VERSION "GB/T 27930-2015 canonical charger/BMS message set (canfd.net reference; extracted 2026-09-05)"

NS_ :

BS_:

BU_: Charger BMS

BO_ 2552689750 CHM: 3 Charger
 SG_ ChargerVersion : 8|16@1+ (1,0) [0|65535] ""  BMS
 SG_ ChargerRevision : 0|8@1+ (1,0) [0|255] ""  BMS

BO_ 2552714996 BHM: 2 Charger
 SG_ MaxChargingVoltage : 0|16@1+ (0.1,0) [0|6553.5] "V" Charger

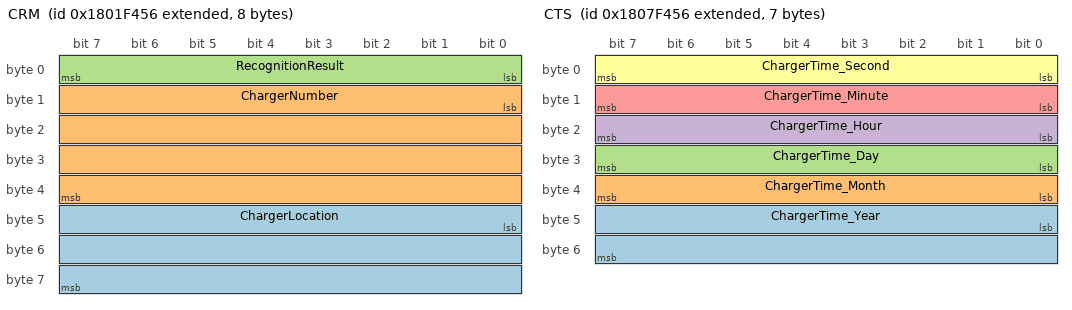
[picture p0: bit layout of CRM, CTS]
BO_ 2550264918 CRM: 8 Charger
 SG_ ChargerLocation : 40|24@1+ (1,0) [0|16777215] ""  BMS
 SG_ ChargerNumber : 8|32@1+ (1,0) [0|4294967295] ""  BMS
 SG_ RecognitionResult : 0|8@1+ (1,0) [0|170] ""  BMS

BO_ 2617442292 BRM: 49 Charger
 SG_ VIN_Copy_17 : 320|8@1+ (1,0) [0|255] "" Charger
 SG_ VIN_Copy_16 : 312|8@1+ (1,0) [0|255] "" Charger
 SG_ VIN_Copy_15 : 304|8@1+ (1,0) [0|255] "" Charger
 SG_ VIN_Copy_14 : 296|8@1+ (1,0) [0|255] "" Charger
 SG_ VIN_Copy_13 : 288|8@1+ (1,0) [0|255] "" Charger
 SG_ VIN_Copy_12 : 280|8@1+ (1,0) [0|255] "" Charger
 SG_ VIN_Copy_11 : 272|8@1+ (1,0) [0|255] "" Charger
 SG_ VIN_Copy_10 : 264|8@1+ (1,0) [0|255] "" Charger
 SG_ VIN_Copy_9 : 256|8@1+ (1,0) [0|255] "" Charger
 SG_ VIN_Copy_8 : 248|8@1+ (1,0) [0|255] "" Charger
 SG_ VIN_Copy_7 : 240|8@1+ (1,0) [0|255] "" Charger
 SG_ VIN_Copy_6 : 232|8@1+ (1,0) [0|255] "" Charger
 SG_ VIN_Copy_5 : 224|8@1+ (1,0) [0|255] "" Charger
 SG_ VIN_Copy_4 : 216|8@1+ (1,0) [0|255] "" Charger
 SG_ VIN_Copy_3 : 208|8@1+ (1,0) [0|255] "" Charger
 SG_ VIN_Copy_2 : 200|8@1+ (1,0) [0|255] "" Charger
 SG_ VIN_Copy_1 : 192|8@1+ (1,0) [0|255] "" Charger
 SG_ BmsSoftwareVersion_Reserved : 368|24@1+ (1,0) [0|16777215] "" Charger
 SG_ BmsSoftwareVersion_CompileYear : 352|16@1+ (1,0) [0|65534] "" Charger
 SG_ BmsSoftwareVersion_CompileMonth : 344|8@1+ (1,0) [1|12] "" Charger
 SG_ BmsSoftwareVersion_CompileDay : 336|8@1+ (1,0) [1|31] "" Charger
 SG_ BmsSoftwareVersion_Serial : 328|8@1+ (1,0) [1|254] "" Charger
 SG_ BRM_Reserved1 : 184|8@1+ (1,0) [0|255] "" Charger
 SG_ Property : 176|8@1+ (1,0) [0|1] "" Charger
 SG_ ChargingFrequency : 152|24@1+ (1,0) [0|16777215] "" Charger
 SG_ ProductionDay : 144|8@1+ (1,0) [0|31] "Days" Charger
 SG_ ProductionMonth : 136|8@1+ (1,0) [1|12] "" Charger
 SG_ ProductionYear : 128|8@1+ (1,1985) [1985|2235] "Years" Charger
 SG_ BatteryPackNumber : 96|32@1+ (1,0) [0|4294967295] "" Charger
 SG_ ManufacturerName : 64|32@1+ (1,0) [0|4294967295] "" Charger
 SG_ BatterySystemVoltage : 48|16@1+ (0.1,0) [0|6553.5] "V" Charger
 SG_ BatterySystemCapacity : 32|16@1+ (0.1,0) [0|6553.5] "Ah" Charger
 SG_ BmsVersion : 8|16@1+ (1,0) [0|65535] "" Charger
 SG_ BmsRevision : 0|8@1+ (1,0) [0|255] "" Charger
 SG_ BatteryType : 24|8@1+ (1,0) [0|255] "" Charger

BO_ 2617704436 BCP: 13 Charger
 SG_ CurrentVehicleBatteryVoltage : 88|16@1+ (0.1,0) [0|6553.5] "V" Charger
 SG_ StatusVehiclePowerStorageBattery : 72|16@1+ (0.1,0) [0|100] "%" Charger
 SG_ MaxPermTemperature : 64|8@1+ (1,-50) [-50|200] "" Charger
 SG_ TotalMaxPermChargingVoltage : 48|16@1+ (0.1,0) [0|6553.5] "V" Charger
 SG_ TotalNominalEnergy : 32|16@1+ (0.1,0) [0|1000] "kWh" Charger
 SG_ MaxPermChargingCurrent : 16|16@1+ (0.1,-400) [-400|6153.5] "A" Charger
 SG_ MaxSingleBattChargingVoltage : 0|16@1+ (0.01,0) [0|24] "V" Charger

BO_ 2550658134 CTS: 7 Charger
 SG_ ChargerTime_Year : 40|16@1+ (1,0) [0|39321] ""  BMS
 SG_ ChargerTime_Month : 32|8@1+ (1,0) [0|18] ""  BMS
 SG_ ChargerTime_Day : 24|8@1+ (1,0) [0|49] ""  BMS
 SG_ ChargerTime_Hour : 16|8@1+ (1,0) [0|36] ""  BMS
 SG_ ChargerTime_Minute : 8|8@1+ (1,0) [0|96] ""  BMS
 SG_ ChargerTime_Second : 0|8@1+ (1,0) [0|96] ""  BMS

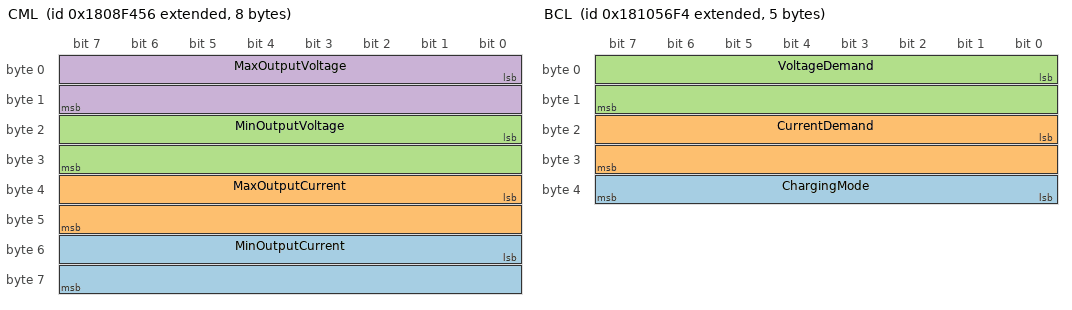
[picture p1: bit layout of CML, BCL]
BO_ 2550723670 CML: 8 Charger
 SG_ MinOutputCurrent : 48|16@1+ (0.1,-400) [-400|6153.5] "A"  BMS
 SG_ MaxOutputCurrent : 32|16@1+ (0.1,-400) [-400|6153.5] "A"  BMS
 SG_ MinOutputVoltage : 16|16@1+ (0.1,0) [0|6553.5] "V"  BMS
 SG_ MaxOutputVoltage : 0|16@1+ (0.1,0) [0|6553.5] "V"  BMS

BO_ 2416531188 BRO: 1 Charger
 SG_ BmsReadyForCharging : 0|8@1+ (1,0) [0|255] "" Charger

BO_ 2416637014 CRO: 1 Charger
 SG_ ChargerReadyForCharging : 0|8@1+ (1,0) [0|255] ""  BMS

BO_ 2551207668 BCL: 5 Charger
 SG_ ChargingMode : 32|8@1+ (1,0) [0|0] "" Charger
 SG_ CurrentDemand : 16|16@1+ (0.1,-400) [-400|6153.5] "A" Charger
 SG_ VoltageDemand : 0|16@1+ (0.1,0) [0|6553.5] "V" Charger

BO_ 2618425332 BCS: 9 Charger
 SG_ EstimatedRemainingChargingTime : 56|16@1+ (1,0) [0|600] "min" Charger
 SG_ CurrentChargeState : 48|8@1+ (1,0) [0|100] "%" Charger
 SG_ SingleBatteryHighestVoltageGroup : 44|4@1+ (1,0) [0|15] "" Charger
 SG_ SingleBatteryHighestVoltage : 32|12@1+ (0.01,0) [0|24] "V" Charger
 SG_ MeasuredChargingCurrent : 16|16@1+ (0.1,-400) [-400|6153.5] "A" Charger
 SG_ MeasuredChargingVoltage : 0|16@1+ (0.1,0) [0|6553.5] "V" Charger

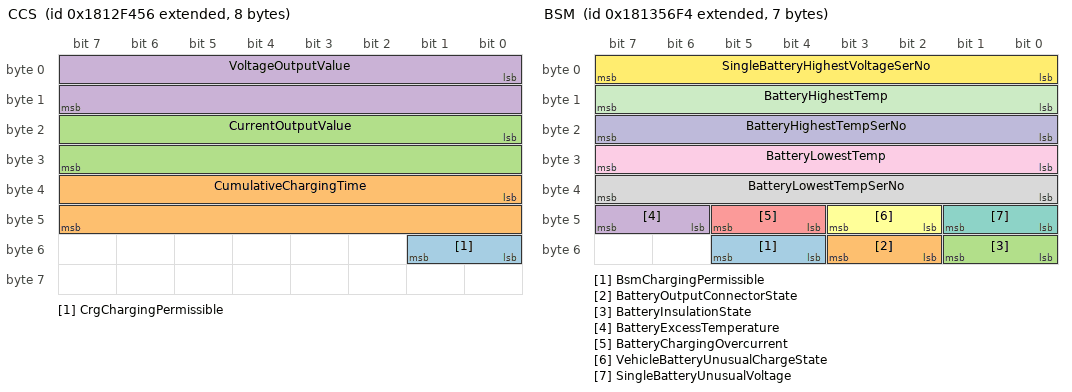
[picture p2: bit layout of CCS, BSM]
BO_ 2551379030 CCS: 8 Charger
 SG_ CrgChargingPermissible : 48|2@1+ (1,0) [0|3] ""  BMS
 SG_ CumulativeChargingTime : 32|16@1+ (1,0) [0|600] "min"  BMS
 SG_ CurrentOutputValue : 16|16@1+ (0.1,-400) [-400|6153.5] "A"  BMS
 SG_ VoltageOutputValue : 0|16@1+ (0.1,0) [0|6553.5] "V"  BMS

BO_ 2551404276 BSM: 7 Charger
 SG_ BsmChargingPermissible : 52|2@1+ (1,0) [0|3] "" Charger
 SG_ BatteryOutputConnectorState : 50|2@1+ (1,0) [0|3] "" Charger
 SG_ BatteryInsulationState : 48|2@1+ (1,0) [0|3] "" Charger
 SG_ BatteryExcessTemperature : 46|2@1+ (1,0) [0|3] "" Charger
 SG_ BatteryChargingOvercurrent : 44|2@1+ (1,0) [0|3] "" Charger
 SG_ VehicleBatteryUnusualChargeState : 42|2@1+ (1,0) [0|3] "" Charger
 SG_ SingleBatteryUnusualVoltage : 40|2@1+ (1,0) [0|3] "" Charger
 SG_ BatteryLowestTempSerNo : 32|8@1+ (1,1) [1|256] "" Charger
 SG_ BatteryLowestTemp : 24|8@1+ (1,-50) [-50|200] "" Charger
 SG_ BatteryHighestTempSerNo : 16|8@1+ (1,1) [1|256] "" Charger
 SG_ BatteryHighestTemp : 8|8@1+ (1,-50) [-50|200] "" Charger
 SG_ SingleBatteryHighestVoltageSerNo : 0|8@1+ (1,1) [1|256] "" Charger

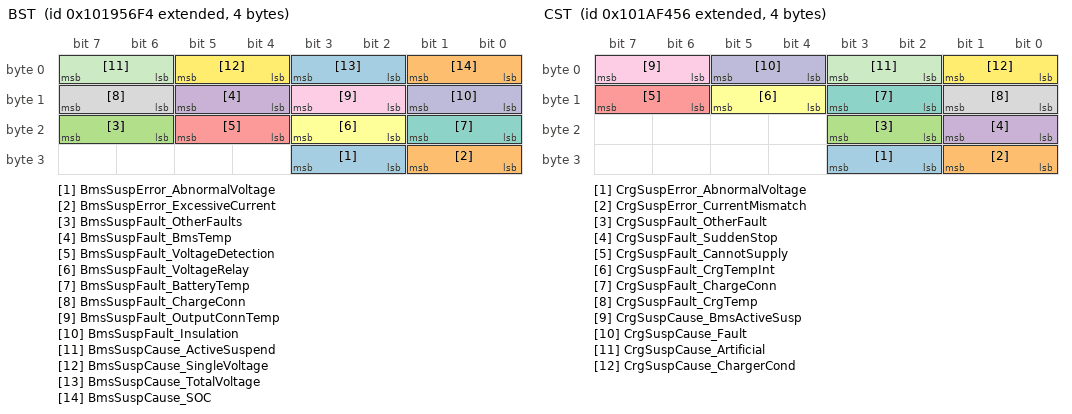
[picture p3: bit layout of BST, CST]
BO_ 2417579764 BST: 4 Charger
 SG_ BmsSuspError_AbnormalVoltage : 26|2@1+ (1,0) [0|3] "" Charger
 SG_ BmsSuspError_ExcessiveCurrent : 24|2@1+ (1,0) [0|3] "" Charger
 SG_ BmsSuspFault_OtherFaults : 22|2@1+ (1,0) [0|3] "" Charger
 SG_ BmsSuspFault_BmsTemp : 12|2@1+ (1,0) [0|3] "" Charger
 SG_ BmsSuspFault_VoltageDetection : 20|2@1+ (1,0) [0|3] "" Charger
 SG_ BmsSuspFault_VoltageRelay : 18|2@1+ (1,0) [0|3] "" Charger
 SG_ BmsSuspFault_BatteryTemp : 16|2@1+ (1,0) [0|3] "" Charger
 SG_ BmsSuspFault_ChargeConn : 14|2@1+ (1,0) [0|3] "" Charger
 SG_ BmsSuspFault_OutputConnTemp : 10|2@1+ (1,0) [0|3] "" Charger
 SG_ BmsSuspFault_Insulation : 8|2@1+ (1,0) [0|3] "" Charger
 SG_ BmsSuspCause_ActiveSuspend : 6|2@1+ (1,0) [0|3] "" Charger
 SG_ BmsSuspCause_SingleVoltage : 4|2@1+ (1,0) [0|3] "" Charger
 SG_ BmsSuspCause_TotalVoltage : 2|2@1+ (1,0) [0|3] "" Charger
 SG_ BmsSuspCause_SOC : 0|2@1+ (1,0) [0|3] "" Charger

BO_ 2417685590 CST: 4 Charger
 SG_ CrgSuspError_AbnormalVoltage : 26|2@1+ (1,0) [0|3] ""  BMS
 SG_ CrgSuspError_CurrentMismatch : 24|2@1+ (1,0) [0|3] ""  BMS
 SG_ CrgSuspFault_OtherFault : 18|2@1+ (1,0) [0|3] ""  BMS
 SG_ CrgSuspFault_SuddenStop : 16|2@1+ (1,0) [0|3] ""  BMS
 SG_ CrgSuspFault_CannotSupply : 14|2@1+ (1,0) [0|3] ""  BMS
 SG_ CrgSuspFault_CrgTempInt : 12|2@1+ (1,0) [0|3] ""  BMS
 SG_ CrgSuspFault_ChargeConn : 10|2@1+ (1,0) [0|3] ""  BMS
 SG_ CrgSuspFault_CrgTemp : 8|2@1+ (1,0) [0|3] ""  BMS
 SG_ CrgSuspCause_BmsActiveSusp : 6|2@1+ (1,0) [0|3] ""  BMS
 SG_ CrgSuspCause_Fault : 4|2@1+ (1,0) [0|3] ""  BMS
 SG_ CrgSuspCause_Artificial : 2|2@1+ (1,0) [0|3] ""  BMS
 SG_ CrgSuspCause_ChargerCond : 0|2@1+ (1,0) [0|3] ""  BMS

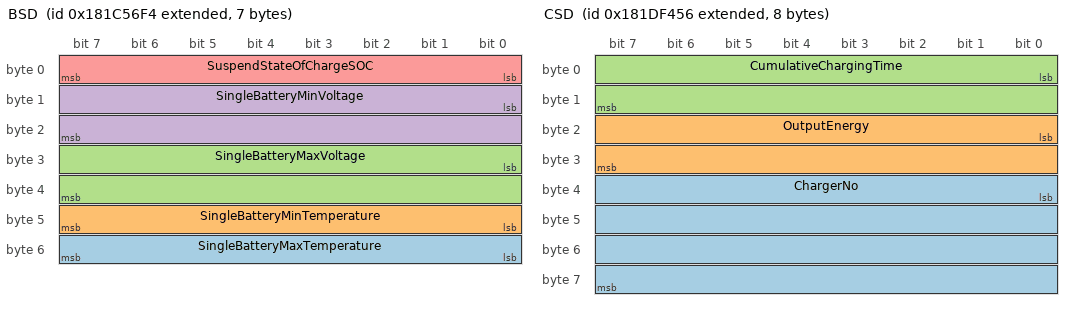
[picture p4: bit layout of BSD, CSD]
BO_ 2551994100 BSD: 7 Charger
 SG_ SingleBatteryMaxTemperature : 48|8@1+ (1,-50) [-50|200] "" Charger
 SG_ SingleBatteryMinTemperature : 40|8@1+ (1,-50) [-50|200] "" Charger
 SG_ SingleBatteryMaxVoltage : 24|16@1+ (0.01,0) [0|24] "V" Charger
 SG_ SingleBatteryMinVoltage : 8|16@1+ (0.01,0) [0|24] "V" Charger
 SG_ SuspendStateOfChargeSOC : 0|8@1+ (1,0) [0|100] "%" Charger

BO_ 2552099926 CSD: 8 Charger
 SG_ ChargerNo : 32|32@1+ (1,1) [1|4294967296] ""  BMS
 SG_ OutputEnergy : 16|16@1+ (0.1,0) [0|1000] "kWh"  BMS
 SG_ CumulativeChargingTime : 0|16@1+ (1,0) [0|600] "min"  BMS
